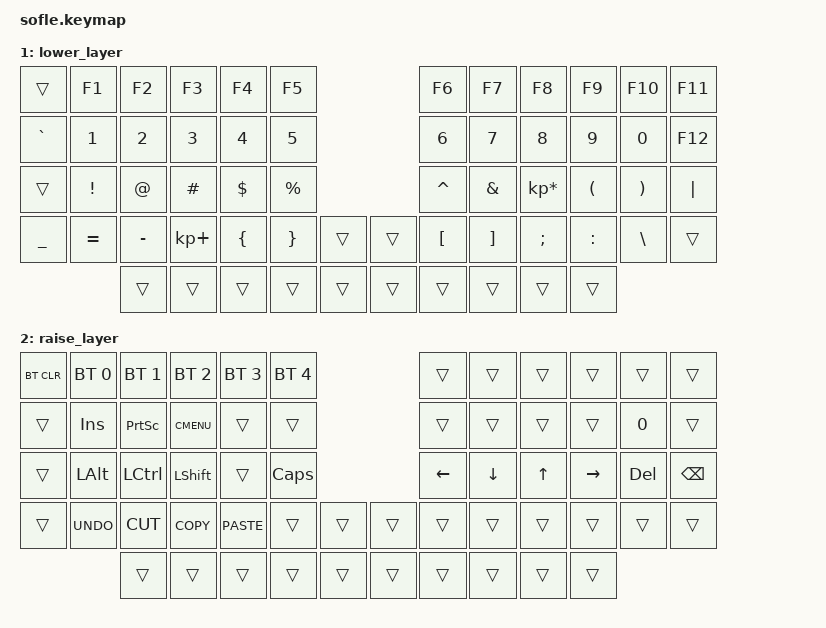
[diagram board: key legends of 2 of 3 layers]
/*
 * Copyright (c) 2020 The ZMK Contributors
 *
 * SPDX-License-Identifier: MIT
 */

#include <behaviors.dtsi>
#include <dt-bindings/zmk/bt.h>
#include <dt-bindings/zmk/keys.h>

/ {
    behaviors {
        mt_impl: mod-tap-by-hold-tap {
            compatible = "zmk,behavior-hold-tap";
            label = "MOD_TAP_BY_HOLD_TAP";
            #binding-cells = <2>;
            tapping-term-ms = <150>;
            quick-tap-ms = <0>;
            flavor = "tap-preferred";
            bindings = <&kp>, <&kp>;
        };
    };

    keymap {
        compatible = "zmk,keymap";

        default_layer {
            // ------------------------------------------------------------------------------------------------------------
            // |  `    |  1  |  2  |  3   |  4   |  5   |                   |  6   |  7    |  8    |  9   |   0   |       |
            // |  ESC  |  Q  |  W  |  E   |  R   |  T   |                   |  Y   |  U    |  I    |  O   |   P   | BKSPC |
            // |  TAB  |  A  |  S  |  D   |  F   |  G   |                   |  H   |  J    |  K    |  L   |   ;   |   '   |
            // | SHIFT |  Z  |  X  |  C   |  V   |  B   |  MUTE  |  |       |  N   |  M    |  ,    |  .   |   /   | SHIFT |
            //               | GUI | ALT  | CTRL | LOWER|  ENTER |  | SPACE | RAISE| CTRL  | ALT   | GUI  |

            bindings = <
&kp GRAVE   &kp N1  &kp N2      &kp N3     &kp N4                 &kp N5                                       &kp N6    &kp N7    &kp N8     &kp N9   &kp N0    &none
&kp TAB     &kp Q   &kp W       &kp E      &kp R                  &kp T                                        &kp Y     &kp U     &kp I      &kp O    &kp P     &kp BSPC
&kp ESCAPE  &kp A   &kp S       &kp D      &kp F                  &kp G                                        &kp H     &kp J     &kp K      &kp L    &kp SEMI  &kp SQT
&kp LSHFT   &kp Z   &kp X       &kp C      &kp V                  &kp B     &kp SPACE    &mt_impl ENTER SPACE  &kp N     &kp M     &kp COMMA  &kp DOT  &kp FSLH  &kp RSHFT
                    &kp C_MUTE  &kp LCTRL  &kp LA(RA(RIGHT_ALT))  &kp LCMD  &mo 1        &mo 2                 &kp RGUI  &kp RALT  &kp RCTRL  &kp A
                                                                   &kp A      &kp B  &kp C &kp D  &kp E

            >;

            sensor-bindings =
                <&inc_dec_kp C_VOLUME_DOWN C_VOLUME_UP>,
                <&inc_dec_kp C_NEXT C_PREV>;
        };

        lower_layer {
            // TODO: Some binds are waiting for shifted keycode support.
            // ------------------------------------------------------------------------------------------------------------
            // |       |  F1 |  F2 |  F3  |  F4  |  F5  |                   |  F6  |  F7   |  F8   |  F9  |  F10  |  F11  |
            // | `     |   1 |   2 |   3  |   4  |   5  |                   |   6  |   7   |   8   |   9  |    0  |  F12  |
            // |       |  !  |  @  |  #   |  $   |  %   |                   |  ^   |  &    |  *    |  (   |   )   |   |   |
            // |       |  =  |  -  |  +   |  {   |  }   |        |  |       |  [   |  ]    |  ;    |  :   |   \   |       |
            //               |     |      |      |      |        |  |       |      |       |       |      |

            bindings = <
&trans     &kp F1     &kp F2     &kp F3       &kp F4    &kp F5                       &kp F6     &kp F7    &kp F8           &kp F9     &kp F10   &kp F11
&kp GRAVE  &kp N1     &kp N2     &kp N3       &kp N4    &kp N5                       &kp N6     &kp N7    &kp N8           &kp N9     &kp N0    &kp F12
&trans     &kp EXCL   &kp AT     &kp HASH     &kp DLLR  &kp PRCNT                    &kp CARET  &kp AMPS  &kp KP_MULTIPLY  &kp LPAR   &kp RPAR  &kp PIPE
&kp UNDER  &kp EQUAL  &kp MINUS  &kp KP_PLUS  &kp LBRC  &kp RBRC   &trans    &trans  &kp LBKT   &kp RBKT  &kp SEMI         &kp COLON  &kp BSLH  &trans
                      &trans     &trans       &trans    &trans     &trans    &trans  &trans     &trans    &trans           &trans
            >;

            sensor-bindings = <&inc_dec_kp C_VOL_UP C_VOL_DN>;
        };

        raise_layer {
            // ------------------------------------------------------------------------------------------------------------
            // |BTCLR| BT1  | BT2  |  BT3  |  BT4  |  BT5 |                |      |      |       |      |       |       |
            // |     | INS  | PSCR | GUI   |       |      |                | PGUP |      |   ^   |      |       |       |
            // |     | ALT  | CTRL | SHIFT |       | CAPS |                | PGDN |   <- |   v   |  ->  |  DEL  | BKSPC |
            // |     | UNDO | CUT  | COPY  | PASTE |      |      |  |      |      |      |       |      |       |       |
            //              |      |       |       |      |      |  |      |      |      |       |      |

            bindings = <
&bt BT_CLR  &bt BT_SEL 0  &bt BT_SEL 1  &bt BT_SEL 2  &bt BT_SEL 3  &bt BT_SEL 4                    &trans    &trans    &trans  &trans     &trans   &trans
&trans      &kp INS       &kp PSCRN     &kp K_CMENU   &trans        &trans                          &trans    &trans    &trans  &trans     &kp N0   &trans
&trans      &kp LALT      &kp LCTRL     &kp LSHFT     &trans        &kp CLCK                        &kp LEFT  &kp DOWN  &kp UP  &kp RIGHT  &kp DEL  &kp BSPC
&trans      &kp K_UNDO    &kp K_CUT     &kp K_COPY    &kp K_PASTE   &trans        &trans    &trans  &trans    &trans    &trans  &trans     &trans   &trans
                          &trans        &trans        &trans        &trans        &trans    &trans  &trans    &trans    &trans  &trans
            >;

            sensor-bindings = <&inc_dec_kp C_VOL_UP C_VOL_DN>;
        };
    };
};
